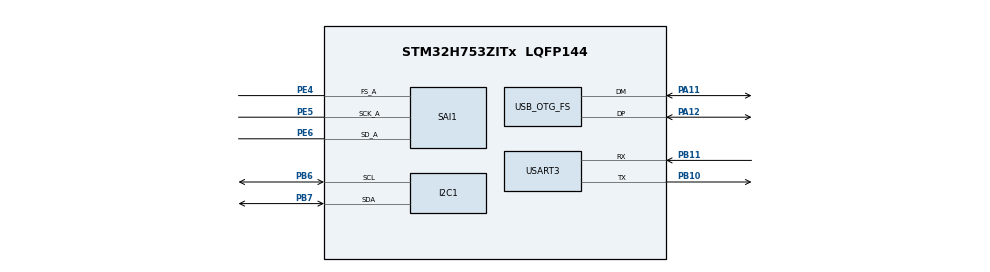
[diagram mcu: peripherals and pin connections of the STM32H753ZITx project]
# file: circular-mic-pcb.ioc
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CORTEX_M7.default_mode_Activation=1
Dma.Request0=SAI1_A
Dma.SAI1_A.0.Direction=DMA_PERIPH_TO_MEMORY
Dma.SAI1_A.0.EventEnable=DISABLE
Dma.SAI1_A.0.FIFOMode=DMA_FIFOMODE_DISABLE
Dma.SAI1_A.0.Instance=DMA1_Stream0
Dma.SAI1_A.0.MemDataAlignment=DMA_MDATAALIGN_WORD
Dma.SAI1_A.0.MemInc=DMA_MINC_ENABLE
Dma.SAI1_A.0.Mode=DMA_CIRCULAR
Dma.SAI1_A.0.PeriphDataAlignment=DMA_PDATAALIGN_WORD
Dma.SAI1_A.0.PeriphInc=DMA_PINC_DISABLE
Dma.SAI1_A.0.Polarity=HAL_DMAMUX_REQ_GEN_RISING
Dma.SAI1_A.0.Priority=DMA_PRIORITY_HIGH
Dma.SAI1_A.0.RequestNumber=1
Dma.SAI1_A.0.SignalID=NONE
Dma.SAI1_A.0.SyncEnable=DISABLE
Dma.SAI1_A.0.SyncPolarity=HAL_DMAMUX_SYNC_NO_EVENT
Dma.SAI1_A.0.SyncRequestNumber=1
Dma.SAI1_A.0.SyncSignalID=NONE
I2C1.I2C_Fall_Time=300
I2C1.I2C_Rise_Time=300
I2C1.Timing=0x80632B3A
Mcu.Family=STM32H7
Mcu.Name=STM32H753ZITx
Mcu.Package=LQFP144
NVIC.DMA1_Stream0_IRQn=true\:0\:0\:false\:false\:true\:false\:true\:true
NVIC.OTG_FS_IRQn=true\:0\:0\:false\:false\:true\:true\:true\:true
NVIC.PriorityGroup=NVIC_PRIORITYGROUP_4
NVIC.SAI1_IRQn=true\:0\:0\:false\:false\:true\:true\:true\:true
PA11.Mode=Device_Only
PA11.Signal=USB_OTG_FS_DM
PA12.Mode=Device_Only
PA12.Signal=USB_OTG_FS_DP
PA13\ (JTMS/SWDIO).Mode=Serial_Wire
PA13\ (JTMS/SWDIO).Signal=DEBUG_JTMS-SWDIO
PA14\ (JTCK/SWCLK).Mode=Serial_Wire
PA14\ (JTCK/SWCLK).Signal=DEBUG_JTCK-SWCLK
PB10.Mode=Asynchronous
PB10.Signal=USART3_TX
PB11.Mode=Asynchronous
PB11.Signal=USART3_RX
PB6.Mode=I2C
PB6.Signal=I2C1_SCL
PB7.Mode=I2C
PB7.Signal=I2C1_SDA
PE4.GPIO_Speed=GPIO_SPEED_FREQ_HIGH
PE4.Mode=SAI_A_Master
PE4.Signal=SAI1_FS_A
PE5.GPIO_Speed=GPIO_SPEED_FREQ_HIGH
PE5.Mode=SAI_A_Master
PE5.Signal=SAI1_SCK_A
PE6.Mode=SAI_A_Master
PE6.Signal=SAI1_SD_A
PH0-OSC_IN\ (PH0).Mode=HSE-External-Oscillator
PH0-OSC_IN\ (PH0).Signal=RCC_OSC_IN
PH1-OSC_OUT\ (PH1).Mode=HSE-External-Oscillator
PH1-OSC_OUT\ (PH1).Signal=RCC_OSC_OUT
ProjectManager.HeapSize=0x200
ProjectManager.StackSize=0x400
ProjectManager.TargetToolchain=STM32CubeIDE
RCC.ADCFreq_Value=49152008.056640625
RCC.APB1Freq_Value=100000000
RCC.APB2Freq_Value=100000000
RCC.APB3Freq_Value=100000000
RCC.APB4Freq_Value=100000000
RCC.CortexFreq_Value=400000000
RCC.D1PPRE=RCC_APB3_DIV2
RCC.D2PPRE1=RCC_APB1_DIV2
RCC.D2PPRE2=RCC_APB2_DIV2
RCC.D3PPRE=RCC_APB4_DIV2
RCC.DIVM1=4
RCC.DIVM2=4
RCC.DIVM3=4
RCC.DIVN1=200
RCC.DIVN2=196
RCC.DIVN3=96
RCC.DIVP2=16
RCC.DIVP3=8
RCC.DIVQ3=8
RCC.EnbaleCSS=true
RCC.HCLKFreq_Value=200000000
RCC.HPRE=RCC_HCLK_DIV2
RCC.HSE_VALUE=16000000
RCC.PLL2FRACN=4981
RCC.PLL3FRACN=0
RCC.PLLFRACN=0
RCC.PLLSourceVirtual=RCC_PLLSOURCE_HSE
RCC.SAI1CLockSelection=RCC_SAI1CLKSOURCE_PLL2
RCC.SYSCLKFreq_VALUE=400000000
RCC.SYSCLKSource=RCC_SYSCLKSOURCE_PLLCLK
RCC.USBCLockSelection=RCC_USBCLKSOURCE_PLL3
RCC.USBFreq_Value=48000000
SAI1.AudioFrequency-SAI_A_Master=SAI_AUDIO_FREQUENCY_48K
SAI1.AudioMode-SAI_A_Master=SAI_MODEMASTER_RX
SAI1.ClockStrobing-SAI_A_Master=SAI_CLOCKSTROBING_RISINGEDGE
SAI1.DataSize-SAI_A_Master=SAI_DATASIZE_32
SAI1.ErrorAudioFreq-SAI_A_Master=0.0 %
SAI1.FSOffset-SAI_A_Master=SAI_FS_BEFOREFIRSTBIT
SAI1.FSPolarity-SAI_A_Master=SAI_FS_ACTIVE_HIGH
SAI1.FrameLength-SAI_A_Master=256
SAI1.Instance-SAI_A_Master=SAI$Index_Block_A
SAI1.MClockEnable-SAI_A_Master=SAI_MASTERCLOCK_DISABLE
SAI1.NoDivider-SAI_A_Master=SAI_MASTERDIVIDER_ENABLE
SAI1.RealAudioFreq-SAI_A_Master=48.0 KHz
SAI1.SlotActive-SAI_A_Master=0x0000FFFF
SAI1.SlotNumber-SAI_A_Master=8
SAI1.SlotSize-SAI_A_Master=SAI_SLOTSIZE_32B
SAI1.VirtualMode-SAI_A_Master=VM_MASTER
SAI1.VirtualSlotActive-SAI_A_Master=SAI_SLOTACTIVE_ALL
USART3.VirtualMode-Asynchronous=VM_ASYNC
USB_OTG_FS.VirtualMode=Device_Only
VP_MEMORYMAP_VS_MEMORYMAP.Mode=CurAppReg
board=custom

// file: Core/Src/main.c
/* USER CODE BEGIN Header */
/**
  ******************************************************************************
  * @file           : main.c
  * @brief          : Main program body
  ******************************************************************************
  * @attention
  *
  * Copyright (c) 2026 STMicroelectronics.
  * All rights reserved.
  *
  * This software is licensed under terms that can be found in the LICENSE file
  * in the root directory of this software component.
  * If no LICENSE file comes with this software, it is provided AS-IS.
  *
  ******************************************************************************
  */
/* USER CODE END Header */
#include "main.h"

/* USER CODE BEGIN Includes */
#include "board_test.h"

/* USER CODE END Includes */

I2C_HandleTypeDef hi2c1;

SAI_HandleTypeDef hsai_BlockA1;
DMA_HandleTypeDef hdma_sai1_a;

UART_HandleTypeDef huart3;

PCD_HandleTypeDef hpcd_USB_OTG_FS;

void SystemClock_Config(void);
static void MPU_Config(void);
static void MX_GPIO_Init(void);
static void MX_DMA_Init(void);
static void MX_SAI1_Init(void);
static void MX_I2C1_Init(void);
static void MX_USB_OTG_FS_PCD_Init(void);
static void MX_USART3_UART_Init(void);

int main(void)
{

  /* MPU Configuration--------------------------------------------------------*/
  MPU_Config();

  /* MCU Configuration--------------------------------------------------------*/

  /* Reset of all peripherals, Initializes the Flash interface and the Systick. */
  HAL_Init();

  /* Configure the system clock */
  SystemClock_Config();

  /* Initialize all configured peripherals */
  MX_GPIO_Init();
  MX_DMA_Init();
  MX_SAI1_Init();
  MX_I2C1_Init();
  MX_USB_OTG_FS_PCD_Init();
  MX_USART3_UART_Init();
  /* USER CODE BEGIN 2 */
  board_test_init();

  /* USER CODE END 2 */

  /* Infinite loop */
  while (1)
  {

    /* USER CODE BEGIN 3 */
    board_test_loop();
  }
  /* USER CODE END 3 */
}

void SystemClock_Config(void)
{
  RCC_OscInitTypeDef RCC_OscInitStruct = {0};
  RCC_ClkInitTypeDef RCC_ClkInitStruct = {0};

  /** Supply configuration update enable
  */
  HAL_PWREx_ConfigSupply(PWR_LDO_SUPPLY);

  /** Configure the main internal regulator output voltage
  */
  __HAL_PWR_VOLTAGESCALING_CONFIG(PWR_REGULATOR_VOLTAGE_SCALE1);

  while(!__HAL_PWR_GET_FLAG(PWR_FLAG_VOSRDY)) {}

  /** Initializes the RCC Oscillators according to the specified parameters
  * in the RCC_OscInitTypeDef structure.
  */
  RCC_OscInitStruct.OscillatorType = RCC_OSCILLATORTYPE_HSE;
  RCC_OscInitStruct.HSEState = RCC_HSE_ON;
  RCC_OscInitStruct.PLL.PLLState = RCC_PLL_ON;
  RCC_OscInitStruct.PLL.PLLSource = RCC_PLLSOURCE_HSE;
  RCC_OscInitStruct.PLL.PLLM = 4;
  RCC_OscInitStruct.PLL.PLLN = 200;
  RCC_OscInitStruct.PLL.PLLP = 2;
  RCC_OscInitStruct.PLL.PLLQ = 2;
  RCC_OscInitStruct.PLL.PLLR = 2;
  RCC_OscInitStruct.PLL.PLLRGE = RCC_PLL1VCIRANGE_2;
  RCC_OscInitStruct.PLL.PLLVCOSEL = RCC_PLL1VCOWIDE;
  RCC_OscInitStruct.PLL.PLLFRACN = 0;
  if (HAL_RCC_OscConfig(&RCC_OscInitStruct) != HAL_OK)
  {
    Error_Handler();
  }

  /** Initializes the CPU, AHB and APB buses clocks
  */
  RCC_ClkInitStruct.ClockType = RCC_CLOCKTYPE_HCLK|RCC_CLOCKTYPE_SYSCLK
                              |RCC_CLOCKTYPE_PCLK1|RCC_CLOCKTYPE_PCLK2
                              |RCC_CLOCKTYPE_D3PCLK1|RCC_CLOCKTYPE_D1PCLK1;
  RCC_ClkInitStruct.SYSCLKSource = RCC_SYSCLKSOURCE_PLLCLK;
  RCC_ClkInitStruct.SYSCLKDivider = RCC_SYSCLK_DIV1;
  RCC_ClkInitStruct.AHBCLKDivider = RCC_HCLK_DIV2;
  RCC_ClkInitStruct.APB3CLKDivider = RCC_APB3_DIV2;
  RCC_ClkInitStruct.APB1CLKDivider = RCC_APB1_DIV2;
  RCC_ClkInitStruct.APB2CLKDivider = RCC_APB2_DIV2;
  RCC_ClkInitStruct.APB4CLKDivider = RCC_APB4_DIV2;

  if (HAL_RCC_ClockConfig(&RCC_ClkInitStruct, FLASH_LATENCY_2) != HAL_OK)
  {
    Error_Handler();
  }

  /** Enables the Clock Security System
  */
  HAL_RCC_EnableCSS();
}

static void MX_I2C1_Init(void)
{

  hi2c1.Instance = I2C1;
  hi2c1.Init.Timing = 0x80632B3A;
  hi2c1.Init.OwnAddress1 = 0;
  hi2c1.Init.AddressingMode = I2C_ADDRESSINGMODE_7BIT;
  hi2c1.Init.DualAddressMode = I2C_DUALADDRESS_DISABLE;
  hi2c1.Init.OwnAddress2 = 0;
  hi2c1.Init.OwnAddress2Masks = I2C_OA2_NOMASK;
  hi2c1.Init.GeneralCallMode = I2C_GENERALCALL_DISABLE;
  hi2c1.Init.NoStretchMode = I2C_NOSTRETCH_DISABLE;
  if (HAL_I2C_Init(&hi2c1) != HAL_OK)
  {
    Error_Handler();
  }

  /** Configure Analogue filter
  */
  if (HAL_I2CEx_ConfigAnalogFilter(&hi2c1, I2C_ANALOGFILTER_ENABLE) != HAL_OK)
  {
    Error_Handler();
  }

  /** Configure Digital filter
  */
  if (HAL_I2CEx_ConfigDigitalFilter(&hi2c1, 0) != HAL_OK)
  {
    Error_Handler();
  }

}

static void MX_SAI1_Init(void)
{

  hsai_BlockA1.Instance = SAI1_Block_A;
  hsai_BlockA1.Init.Protocol = SAI_FREE_PROTOCOL;
  hsai_BlockA1.Init.AudioMode = SAI_MODEMASTER_RX;
  hsai_BlockA1.Init.DataSize = SAI_DATASIZE_32;
  hsai_BlockA1.Init.FirstBit = SAI_FIRSTBIT_MSB;
  hsai_BlockA1.Init.ClockStrobing = SAI_CLOCKSTROBING_RISINGEDGE;
  hsai_BlockA1.Init.Synchro = SAI_ASYNCHRONOUS;
  hsai_BlockA1.Init.OutputDrive = SAI_OUTPUTDRIVE_DISABLE;
  hsai_BlockA1.Init.NoDivider = SAI_MASTERDIVIDER_ENABLE;
  hsai_BlockA1.Init.MckOverSampling = SAI_MCK_OVERSAMPLING_DISABLE;
  hsai_BlockA1.Init.FIFOThreshold = SAI_FIFOTHRESHOLD_EMPTY;
  hsai_BlockA1.Init.AudioFrequency = SAI_AUDIO_FREQUENCY_48K;
  hsai_BlockA1.Init.SynchroExt = SAI_SYNCEXT_DISABLE;
  hsai_BlockA1.Init.MonoStereoMode = SAI_STEREOMODE;
  hsai_BlockA1.Init.CompandingMode = SAI_NOCOMPANDING;
  hsai_BlockA1.Init.PdmInit.Activation = DISABLE;
  hsai_BlockA1.Init.PdmInit.MicPairsNbr = 1;
  hsai_BlockA1.Init.PdmInit.ClockEnable = SAI_PDM_CLOCK1_ENABLE;
  hsai_BlockA1.FrameInit.FrameLength = 256;
  hsai_BlockA1.FrameInit.ActiveFrameLength = 1;
  hsai_BlockA1.FrameInit.FSDefinition = SAI_FS_STARTFRAME;
  hsai_BlockA1.FrameInit.FSPolarity = SAI_FS_ACTIVE_HIGH;
  hsai_BlockA1.FrameInit.FSOffset = SAI_FS_BEFOREFIRSTBIT;
  hsai_BlockA1.SlotInit.FirstBitOffset = 0;
  hsai_BlockA1.SlotInit.SlotSize = SAI_SLOTSIZE_32B;
  hsai_BlockA1.SlotInit.SlotNumber = 8;
  hsai_BlockA1.SlotInit.SlotActive = 0x0000FFFF;
  if (HAL_SAI_Init(&hsai_BlockA1) != HAL_OK)
  {
    Error_Handler();
  }

}

static void MX_USART3_UART_Init(void)
{

  huart3.Instance = USART3;
  huart3.Init.BaudRate = 115200;
  huart3.Init.WordLength = UART_WORDLENGTH_8B;
  huart3.Init.StopBits = UART_STOPBITS_1;
  huart3.Init.Parity = UART_PARITY_NONE;
  huart3.Init.Mode = UART_MODE_TX_RX;
  huart3.Init.HwFlowCtl = UART_HWCONTROL_NONE;
  huart3.Init.OverSampling = UART_OVERSAMPLING_16;
  huart3.Init.OneBitSampling = UART_ONE_BIT_SAMPLE_DISABLE;
  huart3.Init.ClockPrescaler = UART_PRESCALER_DIV1;
  huart3.AdvancedInit.AdvFeatureInit = UART_ADVFEATURE_NO_INIT;
  if (HAL_UART_Init(&huart3) != HAL_OK)
  {
    Error_Handler();
  }
  if (HAL_UARTEx_SetTxFifoThreshold(&huart3, UART_TXFIFO_THRESHOLD_1_8) != HAL_OK)
  {
    Error_Handler();
  }
  if (HAL_UARTEx_SetRxFifoThreshold(&huart3, UART_RXFIFO_THRESHOLD_1_8) != HAL_OK)
  {
    Error_Handler();
  }
  if (HAL_UARTEx_DisableFifoMode(&huart3) != HAL_OK)
  {
    Error_Handler();
  }

}

static void MX_USB_OTG_FS_PCD_Init(void)
{

  hpcd_USB_OTG_FS.Instance = USB_OTG_FS;
  hpcd_USB_OTG_FS.Init.dev_endpoints = 9;
  hpcd_USB_OTG_FS.Init.speed = PCD_SPEED_FULL;
  hpcd_USB_OTG_FS.Init.dma_enable = DISABLE;
  hpcd_USB_OTG_FS.Init.phy_itface = PCD_PHY_EMBEDDED;
  hpcd_USB_OTG_FS.Init.Sof_enable = DISABLE;
  hpcd_USB_OTG_FS.Init.low_power_enable = DISABLE;
  hpcd_USB_OTG_FS.Init.lpm_enable = DISABLE;
  hpcd_USB_OTG_FS.Init.battery_charging_enable = DISABLE;
  hpcd_USB_OTG_FS.Init.vbus_sensing_enable = DISABLE;
  hpcd_USB_OTG_FS.Init.use_dedicated_ep1 = DISABLE;
  if (HAL_PCD_Init(&hpcd_USB_OTG_FS) != HAL_OK)
  {
    Error_Handler();
  }

}

static void MX_DMA_Init(void)
{

  /* DMA controller clock enable */
  __HAL_RCC_DMA1_CLK_ENABLE();

  /* DMA interrupt init */
  /* DMA1_Stream0_IRQn interrupt configuration */
  HAL_NVIC_SetPriority(DMA1_Stream0_IRQn, 0, 0);
  HAL_NVIC_EnableIRQ(DMA1_Stream0_IRQn);

}

static void MX_GPIO_Init(void)
{

  /* GPIO Ports Clock Enable */
  __HAL_RCC_GPIOE_CLK_ENABLE();
  __HAL_RCC_GPIOH_CLK_ENABLE();
  __HAL_RCC_GPIOB_CLK_ENABLE();
  __HAL_RCC_GPIOA_CLK_ENABLE();

}

 /* MPU Configuration */

void MPU_Config(void)
{
  MPU_Region_InitTypeDef MPU_InitStruct = {0};

  /* Disables the MPU */
  HAL_MPU_Disable();

  /** Initializes and configures the Region and the memory to be protected
  */
  MPU_InitStruct.Enable = MPU_REGION_ENABLE;
  MPU_InitStruct.Number = MPU_REGION_NUMBER0;
  MPU_InitStruct.BaseAddress = 0x0;
  MPU_InitStruct.Size = MPU_REGION_SIZE_4GB;
  MPU_InitStruct.SubRegionDisable = 0x87;
  MPU_InitStruct.TypeExtField = MPU_TEX_LEVEL0;
  MPU_InitStruct.AccessPermission = MPU_REGION_NO_ACCESS;
  MPU_InitStruct.DisableExec = MPU_INSTRUCTION_ACCESS_DISABLE;
  MPU_InitStruct.IsShareable = MPU_ACCESS_SHAREABLE;
  MPU_InitStruct.IsCacheable = MPU_ACCESS_NOT_CACHEABLE;
  MPU_InitStruct.IsBufferable = MPU_ACCESS_NOT_BUFFERABLE;

  HAL_MPU_ConfigRegion(&MPU_InitStruct);
  /* Enables the MPU */
  HAL_MPU_Enable(MPU_PRIVILEGED_DEFAULT);

}

void Error_Handler(void)
{
  __disable_irq();
  while (1)
  {
  }
}
